# STM32F105 register map
File version: 1.3
CPU: CM3 r1p1, little endian, no MPU, no FPU, 4 interrupt priority bits
Registers are 32-bit, read-write, reset 0x0 unless marked. A register's access mark holds for its fields unless they carry their own. Offsets are from the block's base; [hi:lo] are bit positions; {n}, {i} and the like mark numbered series; 'fields as' and 'values as' point back to an identical list.

## CRC — CRC calculation unit
Base 0x40023000
0x00 DR reset 0xFFFFFFFF — Data register
  [31:0] DR — Data Register
0x04 IDR — Independent Data register
  [7:0] IDR
0x08 CR wo — Control register
  [0] RESET — Reset bit

## DAC — Digital to analog converter
Base 0x40007400
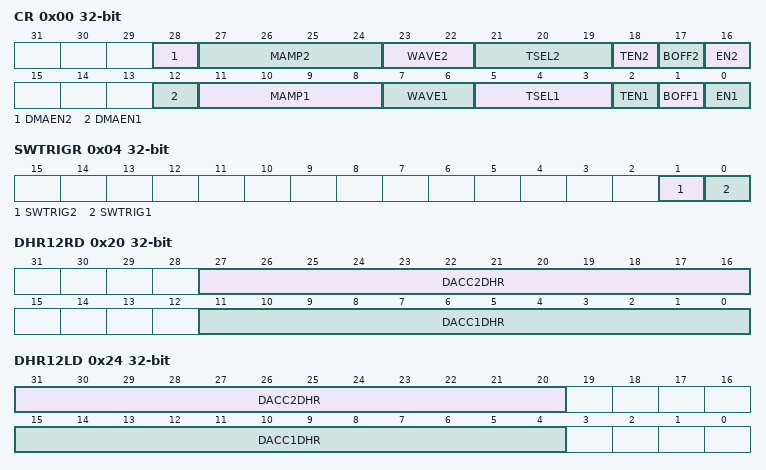
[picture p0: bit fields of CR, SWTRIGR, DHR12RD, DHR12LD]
0x00 CR — Control register (DAC_CR)
  [28] DMAEN2 — DAC channel2 DMA enable
  [27:24] MAMP2 — DAC channel2 mask/amplitude selector
  [23:22] WAVE2 — DAC channel2 noise/triangle wave generation enable
  [21:19] TSEL2 — DAC channel2 trigger selection
  [18] TEN2 — DAC channel2 trigger enable
  [17] BOFF2 — DAC channel2 output buffer disable
  [16] EN2 — DAC channel2 enable
  [12] DMAEN1 — DAC channel1 DMA enable
  [11:8] MAMP1 — DAC channel1 mask/amplitude selector
  [7:6] WAVE1 — DAC channel1 noise/triangle wave generation enable
  [5:3] TSEL1 — DAC channel1 trigger selection
  [2] TEN1 — DAC channel1 trigger enable
  [1] BOFF1 — DAC channel1 output buffer disable
  [0] EN1 — DAC channel1 enable
0x04 SWTRIGR wo — DAC software trigger register (DAC_SWTRIGR)
  [1] SWTRIG2 — DAC channel2 software trigger
  [0] SWTRIG1 — DAC channel1 software trigger
0x08 DHR12R1 — DAC channel1 12-bit right-aligned data holding register(DAC_DHR12R1)
  [11:0] DACC1DHR — DAC channel1 12-bit right-aligned data
0x0C DHR12L1 — DAC channel1 12-bit left aligned data holding register (DAC_DHR12L1)
  [15:4] DACC1DHR — DAC channel1 12-bit left-aligned data
0x10 DHR8R1 — DAC channel1 8-bit right aligned data holding register (DAC_DHR8R1)
  [7:0] DACC1DHR — DAC channel1 8-bit right-aligned data
0x14 DHR12R2 — DAC channel2 12-bit right aligned data holding register (DAC_DHR12R2)
  [11:0] DACC2DHR — DAC channel2 12-bit right-aligned data
0x18 DHR12L2 — DAC channel2 12-bit left aligned data holding register (DAC_DHR12L2)
  [15:4] DACC2DHR — DAC channel2 12-bit left-aligned data
0x1C DHR8R2 — DAC channel2 8-bit right-aligned data holding register (DAC_DHR8R2)
  [7:0] DACC2DHR — DAC channel2 8-bit right-aligned data
0x20 DHR12RD — Dual DAC 12-bit right-aligned data holding register (DAC_DHR12RD), Bits 31:28 Reserved, Bits 15:12 Reserved
  [27:16] DACC2DHR — DAC channel2 12-bit right-aligned data
  [11:0] DACC1DHR — DAC channel1 12-bit right-aligned data
0x24 DHR12LD — DUAL DAC 12-bit left aligned data holding register (DAC_DHR12LD), Bits 19:16 Reserved, Bits 3:0 Reserved
  [31:20] DACC2DHR — DAC channel2 12-bit right-aligned data
  [15:4] DACC1DHR — DAC channel1 12-bit left-aligned data
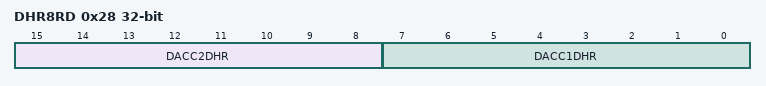
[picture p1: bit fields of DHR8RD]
0x28 DHR8RD — DUAL DAC 8-bit right aligned data holding register (DAC_DHR8RD), Bits 31:16 Reserved
  [15:8] DACC2DHR — DAC channel2 8-bit right-aligned data
  [7:0] DACC1DHR — DAC channel1 8-bit right-aligned data
0x2C DOR1 ro — DAC channel1 data output register (DAC_DOR1)
  [11:0] DACC1DOR — DAC channel1 data output
0x30 DOR2 ro — DAC channel2 data output register (DAC_DOR2)
  [11:0] DACC2DOR — DAC channel2 data output

## DBG — Debug support
Base 0xE0042000
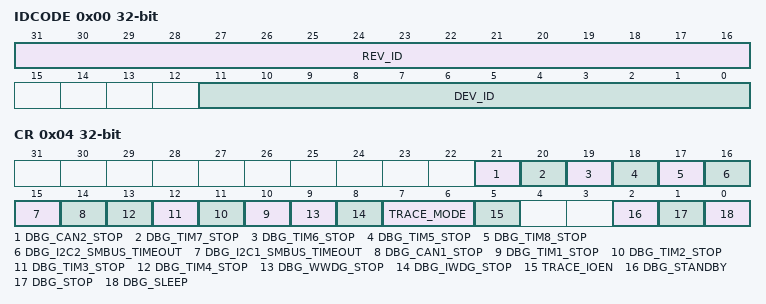
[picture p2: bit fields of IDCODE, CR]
0x00 IDCODE ro — DBGMCU_IDCODE
  [31:16] REV_ID, [11:0] DEV_ID
0x04 CR — DBGMCU_CR
  [21] DBG_CAN2_STOP, [20] DBG_TIM7_STOP, [19] DBG_TIM6_STOP, [18] DBG_TIM5_STOP, [17] DBG_TIM8_STOP, [16] DBG_I2C2_SMBUS_TIMEOUT, [15] DBG_I2C1_SMBUS_TIMEOUT, [14] DBG_CAN1_STOP, [n+9] DBG_TIM{n}_STOP (n=1..4), [9] DBG_WWDG_STOP, [8] DBG_IWDG_STOP, [7:6] TRACE_MODE, [5] TRACE_IOEN, [2] DBG_STANDBY, [1] DBG_STOP, [0] DBG_SLEEP

## DMA1 — DMA controller
Base 0x40020000
Same registers: DMA2 0x40020400
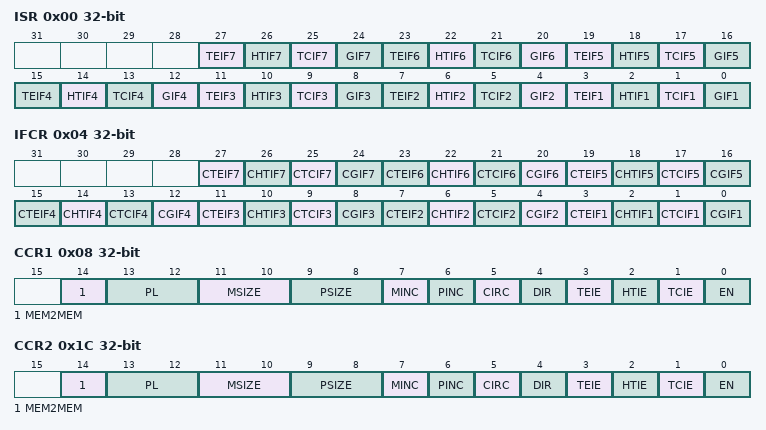
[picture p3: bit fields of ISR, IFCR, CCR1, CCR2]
0x00 ISR ro — DMA interrupt status register (DMA_ISR)
  [4n-1] TEIF{n} (n=1..7) — Channel {n} Transfer Error flag
  [4n-2] HTIF{n} (n=1..7) — Channel {n} Half Transfer Complete flag
  [4n-3] TCIF{n} (n=1..7) — Channel {n} Transfer Complete flag
  [4n-4] GIF{n} (n=1..7) — Channel {n} Global interrupt flag
0x04 IFCR wo — DMA interrupt flag clear register (DMA_IFCR)
  [4n-1] CTEIF{n} (n=1..7) — Channel {n} Transfer Error clear
  [4n-2] CHTIF{n} (n=1..7) — Channel {n} Half Transfer clear
  [4n-3] CTCIF{n} (n=1..7) — Channel {n} Transfer Complete clear
  [4n-4] CGIF{n} (n=1..7) — Channel {n} Global interrupt clear
0x08 CCR1 — DMA channel configuration register (DMA_CCR)
  [14] MEM2MEM — Memory to memory mode
  [13:12] PL — Channel Priority level
  [11:10] MSIZE — Memory size
  [9:8] PSIZE — Peripheral size
  [7] MINC — Memory increment mode
  [6] PINC — Peripheral increment mode
  [5] CIRC — Circular mode
  [4] DIR — Data transfer direction
  [3] TEIE — Transfer error interrupt enable
  [2] HTIE — Half Transfer interrupt enable
  [1] TCIE — Transfer complete interrupt enable
  [0] EN — Channel enable
0x0C CNDTR1 — DMA channel 1 number of data register
  [15:0] NDT — Number of data to transfer
0x10 CPAR1 — DMA channel 1 peripheral address register
  [31:0] PA — Peripheral address
{0x0+0x14*i} CMAR{i} (i=1..7) — DMA channel {i} memory address register
  [31:0] MA — Memory address
0x1C CCR2 — DMA channel configuration register (DMA_CCR)
  fields as CCR1
0x20 CNDTR2 — DMA channel 2 number of data register
  [15:0] NDT — Number of data to transfer
0x24 CPAR2 — DMA channel 2 peripheral address register
  [31:0] PA — Peripheral address
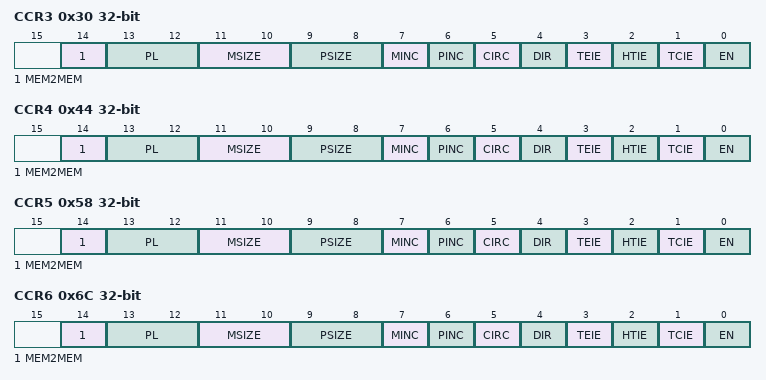
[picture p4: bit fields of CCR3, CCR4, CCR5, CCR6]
0x30 CCR3 — DMA channel configuration register (DMA_CCR)
  fields as CCR1
0x34 CNDTR3 — DMA channel 3 number of data register
  [15:0] NDT — Number of data to transfer
0x38 CPAR3 — DMA channel 3 peripheral address register
  [31:0] PA — Peripheral address
0x44 CCR4 — DMA channel configuration register (DMA_CCR)
  fields as CCR1
0x48 CNDTR4 — DMA channel 4 number of data register
  [15:0] NDT — Number of data to transfer
0x4C CPAR4 — DMA channel 4 peripheral address register
  [31:0] PA — Peripheral address
0x58 CCR5 — DMA channel configuration register (DMA_CCR)
  fields as CCR1
0x5C CNDTR5 — DMA channel 5 number of data register
  [15:0] NDT — Number of data to transfer
0x60 CPAR5 — DMA channel 5 peripheral address register
  [31:0] PA — Peripheral address
0x6C CCR6 — DMA channel configuration register (DMA_CCR)
  fields as CCR1
0x70 CNDTR6 — DMA channel 6 number of data register
  [15:0] NDT — Number of data to transfer
0x74 CPAR6 — DMA channel 6 peripheral address register
  [31:0] PA — Peripheral address
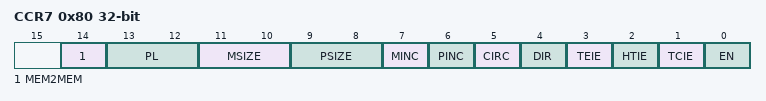
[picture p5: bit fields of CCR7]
0x80 CCR7 — DMA channel configuration register (DMA_CCR)
  fields as CCR1
0x84 CNDTR7 — DMA channel 7 number of data register
  [15:0] NDT — Number of data to transfer
0x88 CPAR7 — DMA channel 7 peripheral address register
  [31:0] PA — Peripheral address

## Notices in the file
Copyright (c) 2024 STMicroelectronics.
SPDX-License-Identifier: Apache-2.0
Licensed under the Apache License, Version 2.0 (the "License");
you may not use this file except in compliance with the License.
You may obtain a copy of the License at
http://www.apache.org/licenses/LICENSE-2.0
Unless required by applicable law or agreed to in writing, software
distributed under the License is distributed on an "AS IS" BASIS,
WITHOUT WARRANTIES OR CONDITIONS OF ANY KIND, either express or implied.
See the License for the specific language governing permissions and
limitations under the License.
